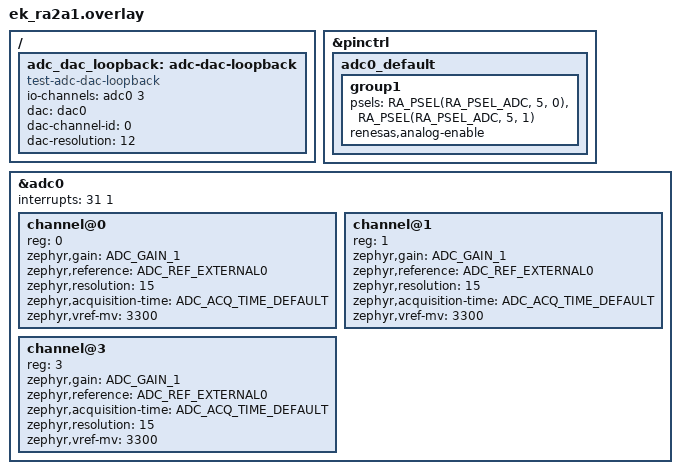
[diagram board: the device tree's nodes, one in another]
/*
 * Copyright (c) 2025 Renesas Electronics Corporation
 *
 * SPDX-License-Identifier: Apache-2.0
 */

&pinctrl {
	adc0_default: adc0_default {
		group1 {
			/* input */
			psels = <RA_PSEL(RA_PSEL_ADC, 5, 0)>,
				<RA_PSEL(RA_PSEL_ADC, 5, 1)>;
			renesas,analog-enable;
		};
	};
};

&adc0 {
	status = "okay";
	#address-cells = <1>;
	#size-cells = <0>;
	interrupts = <31 1>;
	interrupt-names = "scanend";

	/*
	 * Channel 0 is used in single ended mode, with 15 bit resolution
	 */
	channel@0 {
		reg = <0>;
		zephyr,gain = "ADC_GAIN_1";
		zephyr,reference = "ADC_REF_EXTERNAL0";
		zephyr,resolution = <15>;
		zephyr,acquisition-time = <ADC_ACQ_TIME_DEFAULT>;
		zephyr,vref-mv = <3300>;
	};

	/*
	 * Channel 1 is used in single ended mode, with 15 bit resolution
	 */
	channel@1 {
		reg = <1>;
		zephyr,gain = "ADC_GAIN_1";
		zephyr,reference = "ADC_REF_EXTERNAL0";
		zephyr,resolution = <15>;
		zephyr,acquisition-time = <ADC_ACQ_TIME_DEFAULT>;
		zephyr,vref-mv = <3300>;
	};

	/*
	 * Channel 3 is used in single ended mode, with 15 bit resolution
	 */
	channel@3 {
		reg = <3>;
		zephyr,gain = "ADC_GAIN_1";
		zephyr,reference = "ADC_REF_EXTERNAL0";
		zephyr,acquisition-time = <ADC_ACQ_TIME_DEFAULT>;
		zephyr,resolution = <15>;
		zephyr,vref-mv = <3300>;
	};
};

/ {
	adc_dac_loopback: adc-dac-loopback {
		compatible = "test-adc-dac-loopback";
		io-channels = <&adc0 3>;
		dac = <&dac0>;
		dac-channel-id = <0>;
		dac-resolution = <12>;
	};
};
